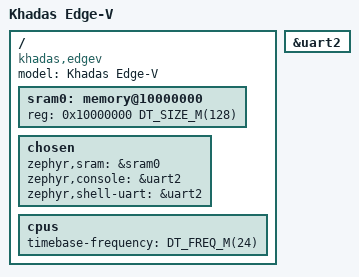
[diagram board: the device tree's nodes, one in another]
/*
 * Copyright 2022 Huawei France Technologies SASU
 *
 * SPDX-License-Identifier: Apache-2.0
 */

/dts-v1/;

#include <freq.h>
#include <rockchip/rk3399_a53.dtsi>

/ {
	model = "Khadas Edge-V";
	compatible = "khadas,edgev";

	sram0: memory@10000000 {
		reg = <0x10000000 DT_SIZE_M(128)>;
	};

	chosen {
		zephyr,sram = &sram0;
		zephyr,console = &uart2;
		zephyr,shell-uart = &uart2;
	};

	cpus {
		timebase-frequency = <DT_FREQ_M(24)>;

		/delete-node/ cpu@1;
		/delete-node/ cpu@2;
		/delete-node/ cpu@3;
	};
};

&uart2 {
	status = "okay";
};
